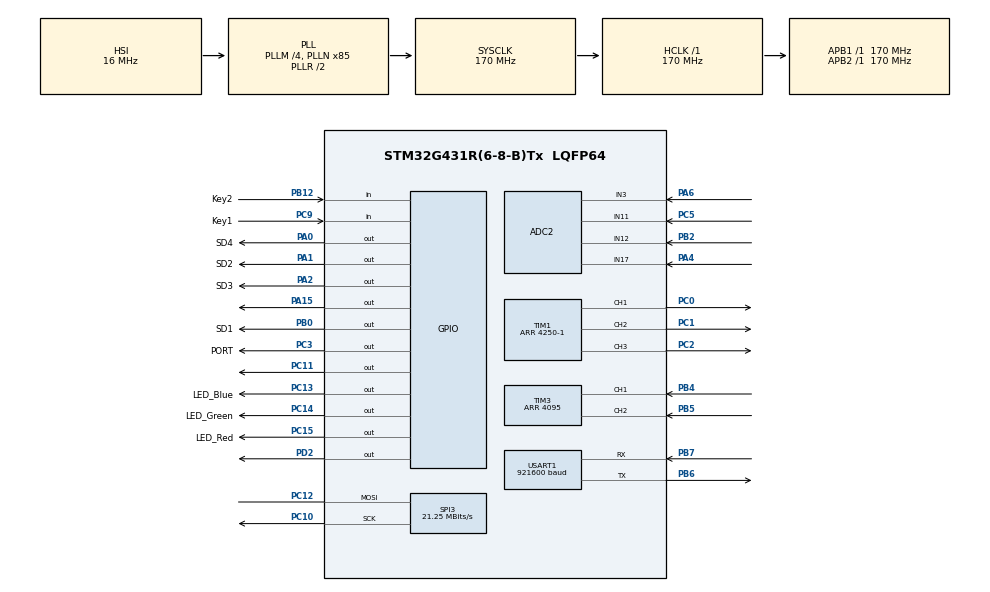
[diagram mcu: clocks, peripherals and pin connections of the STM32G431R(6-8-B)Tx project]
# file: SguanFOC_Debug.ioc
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ADC2.EnableInjectedConversion=ENABLE
ADC2.EnableRegularConversion=DISABLE
ADC2.ExternalTrigInjecConv=ADC_INJECTED_SOFTWARE_START
ADC2.InjNumberOfConversion=4
ADC2.InjectedChannel-3\#ChannelInjectedConversion=ADC_CHANNEL_11
ADC2.InjectedChannel-4\#ChannelInjectedConversion=ADC_CHANNEL_3
ADC2.InjectedChannel-5\#ChannelInjectedConversion=ADC_CHANNEL_17
ADC2.InjectedChannel-7\#ChannelInjectedConversion=ADC_CHANNEL_12
ADC2.InjectedOffsetNumber-3\#ChannelInjectedConversion=ADC_OFFSET_NONE
ADC2.InjectedOffsetNumber-4\#ChannelInjectedConversion=ADC_OFFSET_NONE
ADC2.InjectedOffsetNumber-5\#ChannelInjectedConversion=ADC_OFFSET_NONE
ADC2.InjectedOffsetNumber-7\#ChannelInjectedConversion=ADC_OFFSET_NONE
ADC2.InjectedRank-3\#ChannelInjectedConversion=1
ADC2.InjectedRank-4\#ChannelInjectedConversion=2
ADC2.InjectedRank-5\#ChannelInjectedConversion=3
ADC2.InjectedRank-7\#ChannelInjectedConversion=4
ADC2.InjectedSamplingTime-3\#ChannelInjectedConversion=ADC_SAMPLETIME_2CYCLES_5
ADC2.InjectedSamplingTime-4\#ChannelInjectedConversion=ADC_SAMPLETIME_2CYCLES_5
ADC2.InjectedSamplingTime-5\#ChannelInjectedConversion=ADC_SAMPLETIME_2CYCLES_5
ADC2.InjectedSamplingTime-7\#ChannelInjectedConversion=ADC_SAMPLETIME_2CYCLES_5
ADC2.injectedQueueMode=DISABLE
Dma.Request0=USART1_RX
Dma.Request1=SPI3_TX
Dma.Request2=USART1_TX
Dma.SPI3_TX.1.Direction=DMA_MEMORY_TO_PERIPH
Dma.SPI3_TX.1.EventEnable=DISABLE
Dma.SPI3_TX.1.Instance=DMA1_Channel4
Dma.SPI3_TX.1.MemDataAlignment=DMA_MDATAALIGN_BYTE
Dma.SPI3_TX.1.MemInc=DMA_MINC_ENABLE
Dma.SPI3_TX.1.Mode=DMA_NORMAL
Dma.SPI3_TX.1.PeriphDataAlignment=DMA_PDATAALIGN_BYTE
Dma.SPI3_TX.1.PeriphInc=DMA_PINC_DISABLE
Dma.SPI3_TX.1.Polarity=HAL_DMAMUX_REQ_GEN_RISING
Dma.SPI3_TX.1.Priority=DMA_PRIORITY_LOW
Dma.SPI3_TX.1.RequestNumber=1
Dma.SPI3_TX.1.SignalID=NONE
Dma.SPI3_TX.1.SyncEnable=DISABLE
Dma.SPI3_TX.1.SyncPolarity=HAL_DMAMUX_SYNC_NO_EVENT
Dma.SPI3_TX.1.SyncRequestNumber=1
Dma.SPI3_TX.1.SyncSignalID=NONE
Dma.USART1_RX.0.Direction=DMA_PERIPH_TO_MEMORY
Dma.USART1_RX.0.EventEnable=DISABLE
Dma.USART1_RX.0.Instance=DMA1_Channel1
Dma.USART1_RX.0.MemDataAlignment=DMA_MDATAALIGN_BYTE
Dma.USART1_RX.0.MemInc=DMA_MINC_ENABLE
Dma.USART1_RX.0.Mode=DMA_NORMAL
Dma.USART1_RX.0.PeriphDataAlignment=DMA_PDATAALIGN_BYTE
Dma.USART1_RX.0.PeriphInc=DMA_PINC_DISABLE
Dma.USART1_RX.0.Polarity=HAL_DMAMUX_REQ_GEN_RISING
Dma.USART1_RX.0.Priority=DMA_PRIORITY_LOW
Dma.USART1_RX.0.RequestNumber=1
Dma.USART1_RX.0.SignalID=NONE
Dma.USART1_RX.0.SyncEnable=DISABLE
Dma.USART1_RX.0.SyncPolarity=HAL_DMAMUX_SYNC_NO_EVENT
Dma.USART1_RX.0.SyncRequestNumber=1
Dma.USART1_RX.0.SyncSignalID=NONE
Dma.USART1_TX.2.Direction=DMA_MEMORY_TO_PERIPH
Dma.USART1_TX.2.EventEnable=DISABLE
Dma.USART1_TX.2.Instance=DMA1_Channel2
Dma.USART1_TX.2.MemDataAlignment=DMA_MDATAALIGN_BYTE
Dma.USART1_TX.2.MemInc=DMA_MINC_ENABLE
Dma.USART1_TX.2.Mode=DMA_NORMAL
Dma.USART1_TX.2.PeriphDataAlignment=DMA_PDATAALIGN_BYTE
Dma.USART1_TX.2.PeriphInc=DMA_PINC_DISABLE
Dma.USART1_TX.2.Polarity=HAL_DMAMUX_REQ_GEN_RISING
Dma.USART1_TX.2.Priority=DMA_PRIORITY_LOW
Dma.USART1_TX.2.RequestNumber=1
Dma.USART1_TX.2.SignalID=NONE
Dma.USART1_TX.2.SyncEnable=DISABLE
Dma.USART1_TX.2.SyncPolarity=HAL_DMAMUX_SYNC_NO_EVENT
Dma.USART1_TX.2.SyncRequestNumber=1
Dma.USART1_TX.2.SyncSignalID=NONE
Mcu.Family=STM32G4
Mcu.Name=STM32G431R(6-8-B)Tx
Mcu.Package=LQFP64
NVIC.ADC1_2_IRQn=true\:2\:0\:true\:false\:true\:true\:true\:true
NVIC.DMA1_Channel1_IRQn=true\:0\:0\:false\:false\:true\:false\:true\:true
NVIC.DMA1_Channel2_IRQn=true\:0\:0\:false\:false\:true\:false\:true\:true
NVIC.DMA1_Channel4_IRQn=true\:0\:0\:false\:false\:true\:false\:true\:true
NVIC.PriorityGroup=NVIC_PRIORITYGROUP_4
NVIC.SPI3_IRQn=true\:5\:0\:true\:false\:true\:true\:true\:true
NVIC.TIM1_UP_TIM16_IRQn=true\:0\:0\:false\:false\:true\:true\:true\:true
NVIC.TIM2_IRQn=true\:1\:0\:true\:false\:true\:true\:true\:true
NVIC.USART1_IRQn=true\:5\:0\:true\:false\:true\:true\:true\:true
PA0.GPIO_Label=SD4
PA0.GPIO_PuPd=GPIO_PULLDOWN
PA0.Signal=GPIO_Output
PA1.GPIO_Label=SD2
PA1.GPIO_PuPd=GPIO_PULLDOWN
PA1.Signal=GPIO_Output
PA13.Mode=Serial_Wire
PA13.Signal=SYS_JTMS-SWDIO
PA14.Mode=Serial_Wire
PA14.Signal=SYS_JTCK-SWCLK
PA15.GPIO_Speed=GPIO_SPEED_FREQ_VERY_HIGH
PA15.PinState=GPIO_PIN_SET
PA15.Signal=GPIO_Output
PA2.GPIO_Label=SD3
PA2.GPIO_PuPd=GPIO_PULLDOWN
PA2.Signal=GPIO_Output
PA4.Mode=IN17-Single-Ended
PA4.Signal=ADC2_IN17
PA6.Mode=IN3-Single-Ended
PA6.Signal=ADC2_IN3
PB0.GPIO_Label=SD1
PB0.GPIO_PuPd=GPIO_PULLDOWN
PB0.Signal=GPIO_Output
PB12.GPIO_Label=Key2
PB12.GPIO_PuPd=GPIO_NOPULL
PB12.Signal=GPIO_Input
PB2.Mode=IN12-Single-Ended
PB2.Signal=ADC2_IN12
PB4.Signal=S_TIM3_CH1
PB5.Signal=S_TIM3_CH2
PB6.GPIO_FM6=SYSCFG_FASTMODEPLUS_PB6
PB6.GPIO_Speed=GPIO_SPEED_FREQ_VERY_HIGH
PB6.Mode=Asynchronous
PB6.Signal=USART1_TX
PB7.GPIO_FM7=SYSCFG_FASTMODEPLUS_PB7
PB7.GPIO_Speed=GPIO_SPEED_FREQ_VERY_HIGH
PB7.Mode=Asynchronous
PB7.Signal=USART1_RX
PC0.GPIO_Speed=GPIO_SPEED_FREQ_VERY_HIGH
PC0.Signal=S_TIM1_CH1
PC1.GPIO_Speed=GPIO_SPEED_FREQ_VERY_HIGH
PC1.Signal=S_TIM1_CH2
PC10.Mode=Simplex_Bidirectional_Master
PC10.Signal=SPI3_SCK
PC11.GPIO_Speed=GPIO_SPEED_FREQ_VERY_HIGH
PC11.Signal=GPIO_Output
PC12.Mode=Simplex_Bidirectional_Master
PC12.Signal=SPI3_MOSI
PC13.GPIO_Label=LED_Blue
PC13.GPIO_PuPd=GPIO_PULLUP
PC13.PinState=GPIO_PIN_SET
PC13.Signal=GPIO_Output
PC14-OSC32_IN.GPIO_Label=LED_Green
PC14-OSC32_IN.GPIO_PuPd=GPIO_PULLUP
PC14-OSC32_IN.PinState=GPIO_PIN_SET
PC14-OSC32_IN.Signal=GPIO_Output
PC15-OSC32_OUT.GPIO_Label=LED_Red
PC15-OSC32_OUT.GPIO_PuPd=GPIO_PULLUP
PC15-OSC32_OUT.PinState=GPIO_PIN_SET
PC15-OSC32_OUT.Signal=GPIO_Output
PC2.GPIO_Speed=GPIO_SPEED_FREQ_VERY_HIGH
PC2.Signal=S_TIM1_CH3
PC3.GPIO_Label=PORT
PC3.GPIO_PuPd=GPIO_PULLDOWN
PC3.GPIO_Speed=GPIO_SPEED_FREQ_VERY_HIGH
PC3.Signal=GPIO_Output
PC5.Mode=IN11-Single-Ended
PC5.Signal=ADC2_IN11
PC9.GPIO_Label=Key1
PC9.GPIO_PuPd=GPIO_NOPULL
PC9.Signal=GPIO_Input
PD2.GPIO_Speed=GPIO_SPEED_FREQ_VERY_HIGH
PD2.Signal=GPIO_Output
PF0-OSC_IN.Mode=HSE-External-Oscillator
PF0-OSC_IN.Signal=RCC_OSC_IN
PF1-OSC_OUT.Mode=HSE-External-Oscillator
PF1-OSC_OUT.Signal=RCC_OSC_OUT
ProjectManager.HeapSize=0x200
ProjectManager.StackSize=0x400
ProjectManager.TargetToolchain=MDK-ARM V5.32
RCC.ADC12Freq_Value=170000000
RCC.AHBFreq_Value=170000000
RCC.APB1Freq_Value=170000000
RCC.APB1TimFreq_Value=170000000
RCC.APB2Freq_Value=170000000
RCC.APB2TimFreq_Value=170000000
RCC.CortexFreq_Value=170000000
RCC.EXTERNAL_CLOCK_VALUE=12288000
RCC.HCLKFreq_Value=170000000
RCC.HSE_VALUE=8000000
RCC.HSI48_VALUE=48000000
RCC.HSI_VALUE=16000000
RCC.LSE_VALUE=32768
RCC.PLLM=RCC_PLLM_DIV4
RCC.PLLN=85
RCC.SYSCLKFreq_VALUE=170000000
RCC.SYSCLKSource=RCC_SYSCLKSOURCE_PLLCLK
RCC.USBFreq_Value=170000000
RCC.VCOOutputFreq_Value=340000000
SH.S_TIM1_CH1.0=TIM1_CH1,PWM Generation1 CH1
SH.S_TIM1_CH2.0=TIM1_CH2,PWM Generation2 CH2
SH.S_TIM1_CH3.0=TIM1_CH3,PWM Generation3 CH3
SH.S_TIM3_CH1.0=TIM3_CH1,Encoder_Interface
SH.S_TIM3_CH2.0=TIM3_CH2,Encoder_Interface
SPI3.BaudRatePrescaler=SPI_BAUDRATEPRESCALER_8
SPI3.CalculateBaudRate=21.25 MBits/s
SPI3.DataSize=SPI_DATASIZE_8BIT
SPI3.Direction=SPI_DIRECTION_1LINE
SPI3.Mode=SPI_MODE_MASTER
SPI3.VirtualType=VM_MASTER
TIM1.AutoReloadPreload=TIM_AUTORELOAD_PRELOAD_ENABLE
TIM1.Channel-PWM\ Generation1\ CH1=TIM_CHANNEL_1
TIM1.Channel-PWM\ Generation2\ CH2=TIM_CHANNEL_2
TIM1.Channel-PWM\ Generation3\ CH3=TIM_CHANNEL_3
TIM1.CounterMode=TIM_COUNTERMODE_CENTERALIGNED1
TIM1.OCMode_PWM-PWM\ Generation1\ CH1=TIM_OCMODE_PWM2
TIM1.OCMode_PWM-PWM\ Generation2\ CH2=TIM_OCMODE_PWM2
TIM1.OCMode_PWM-PWM\ Generation3\ CH3=TIM_OCMODE_PWM2
TIM1.PeriodNoDither=4250-1
TIM1.RepetitionCounter=2-1
TIM1.TIM_MasterOutputTrigger=TIM_TRGO_UPDATE
TIM2.AutoReloadPreload=TIM_AUTORELOAD_PRELOAD_ENABLE
TIM2.PeriodNoDither=1000-1
TIM2.Prescaler=170-1
TIM3.EncoderMode=TIM_ENCODERMODE_TI12
TIM3.PeriodNoDither=4095
USART1.BaudRate=921600
USART1.VirtualMode-Asynchronous=VM_ASYNC
VP_SYS_VS_DBSignals.Mode=DisableDeadBatterySignals
VP_TIM1_VS_ClockSourceINT.Mode=Internal
VP_TIM2_VS_ClockSourceINT.Mode=Internal
board=custom

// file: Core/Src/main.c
/* USER CODE BEGIN Header */
/**
  ******************************************************************************
  * @file           : main.c
  * @brief          : Main program body
  ******************************************************************************
  * @attention
  *
  * Copyright (c) 2026 STMicroelectronics.
  * All rights reserved.
  *
  * This software is licensed under terms that can be found in the LICENSE file
  * in the root directory of this software component.
  * If no LICENSE file comes with this software, it is provided AS-IS.
  *
  ******************************************************************************
  */
/* USER CODE END Header */
#include "main.h"
#include "adc.h"
#include "dma.h"
#include "spi.h"
#include "tim.h"
#include "usart.h"
#include "gpio.h"

/* USER CODE BEGIN Includes */
#include "SguanFOC.h"
/* USER CODE END Includes */

void SystemClock_Config(void);

/* USER CODE BEGIN 0 */
uint16_t Encoder_GetCount(void) {
    return (uint16_t)(__HAL_TIM_GET_COUNTER(&htim3));
}

float SS_Encoder_GetRad(void) {
    uint16_t count = Encoder_GetCount();
    // 确保使用浮点运算
    float rad = ((float)count) * (2.0f * Value_PI / 4096.0f);
    return rad;
}
/* USER CODE END 0 */

int main(void)
{

  /* MCU Configuration--------------------------------------------------------*/

  /* Reset of all peripherals, Initializes the Flash interface and the Systick. */
  HAL_Init();

  /* Configure the system clock */
  SystemClock_Config();

  /* Initialize all configured peripherals */
  MX_GPIO_Init();
  MX_DMA_Init();
  MX_USART1_UART_Init();
  MX_TIM1_Init();
  MX_ADC2_Init();
  MX_SPI3_Init();
  MX_TIM3_Init();
  MX_TIM2_Init();
  /* USER CODE BEGIN 2 */
  HAL_TIM_Base_Start_IT(&htim1);
  HAL_TIM_Base_Start_IT(&htim2);
  HAL_UARTEx_ReceiveToIdle_DMA(&huart1, Sguan_PrintfBuff, sizeof(Sguan_PrintfBuff));
  __HAL_DMA_DISABLE_IT(huart1.hdmarx, DMA_IT_HT);
  HAL_GPIO_WritePin(SD4_GPIO_Port,SD4_Pin,GPIO_PIN_SET);
  /* USER CODE END 2 */

  /* Infinite loop */
  /* USER CODE BEGIN WHILE */
  Sguan.mode = Velocity_OPEN_MODE;       // LADRC线自抗扰“速度环”补偿系数
  while (1)
  {
    SguanFOC_main_Loop();
    /* USER CODE END WHILE */

  }
}

void SystemClock_Config(void)
{
  RCC_OscInitTypeDef RCC_OscInitStruct = {0};
  RCC_ClkInitTypeDef RCC_ClkInitStruct = {0};

  /** Configure the main internal regulator output voltage
  */
  HAL_PWREx_ControlVoltageScaling(PWR_REGULATOR_VOLTAGE_SCALE1_BOOST);

  /** Initializes the RCC Oscillators according to the specified parameters
  * in the RCC_OscInitTypeDef structure.
  */
  RCC_OscInitStruct.OscillatorType = RCC_OSCILLATORTYPE_HSI;
  RCC_OscInitStruct.HSIState = RCC_HSI_ON;
  RCC_OscInitStruct.HSICalibrationValue = RCC_HSICALIBRATION_DEFAULT;
  RCC_OscInitStruct.PLL.PLLState = RCC_PLL_ON;
  RCC_OscInitStruct.PLL.PLLSource = RCC_PLLSOURCE_HSI;
  RCC_OscInitStruct.PLL.PLLM = RCC_PLLM_DIV4;
  RCC_OscInitStruct.PLL.PLLN = 85;
  RCC_OscInitStruct.PLL.PLLP = RCC_PLLP_DIV2;
  RCC_OscInitStruct.PLL.PLLQ = RCC_PLLQ_DIV2;
  RCC_OscInitStruct.PLL.PLLR = RCC_PLLR_DIV2;
  if (HAL_RCC_OscConfig(&RCC_OscInitStruct) != HAL_OK)
  {
    Error_Handler();
  }

  /** Initializes the CPU, AHB and APB buses clocks
  */
  RCC_ClkInitStruct.ClockType = RCC_CLOCKTYPE_HCLK|RCC_CLOCKTYPE_SYSCLK
                              |RCC_CLOCKTYPE_PCLK1|RCC_CLOCKTYPE_PCLK2;
  RCC_ClkInitStruct.SYSCLKSource = RCC_SYSCLKSOURCE_PLLCLK;
  RCC_ClkInitStruct.AHBCLKDivider = RCC_SYSCLK_DIV1;
  RCC_ClkInitStruct.APB1CLKDivider = RCC_HCLK_DIV1;
  RCC_ClkInitStruct.APB2CLKDivider = RCC_HCLK_DIV1;

  if (HAL_RCC_ClockConfig(&RCC_ClkInitStruct, FLASH_LATENCY_4) != HAL_OK)
  {
    Error_Handler();
  }
}

void Error_Handler(void)
{
  __disable_irq();
  while (1)
  {
  }
}
